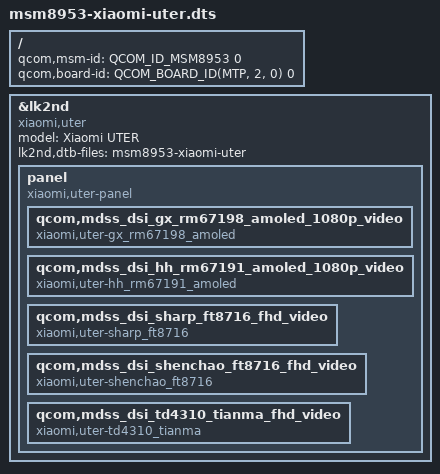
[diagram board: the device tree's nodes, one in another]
// SPDX-License-Identifier: GPL-2.0-only

/dts-v1/;

#include <skeleton64.dtsi>
#include <lk2nd.dtsi>

/ {
	qcom,msm-id = <QCOM_ID_MSM8953 0>;
	qcom,board-id = <QCOM_BOARD_ID(MTP, 2, 0) 0>;
};

&lk2nd {
	model = "Xiaomi UTER";
	compatible = "xiaomi,uter";

	lk2nd,dtb-files = "msm8953-xiaomi-uter";

	panel {
		compatible = "xiaomi,uter-panel", "lk2nd,panel";

		qcom,mdss_dsi_gx_rm67198_amoled_1080p_video {
			compatible = "xiaomi,uter-gx_rm67198_amoled";
		};
		qcom,mdss_dsi_hh_rm67191_amoled_1080p_video {
			compatible = "xiaomi,uter-hh_rm67191_amoled";
		};
		qcom,mdss_dsi_sharp_ft8716_fhd_video {
			compatible = "xiaomi,uter-sharp_ft8716";
		};
		qcom,mdss_dsi_shenchao_ft8716_fhd_video {
			compatible = "xiaomi,uter-shenchao_ft8716";
		};
		qcom,mdss_dsi_td4310_tianma_fhd_video {
			compatible = "xiaomi,uter-td4310_tianma";
		};
	};
};
